VERSION ""

NS_ :

BS_:

BU_:

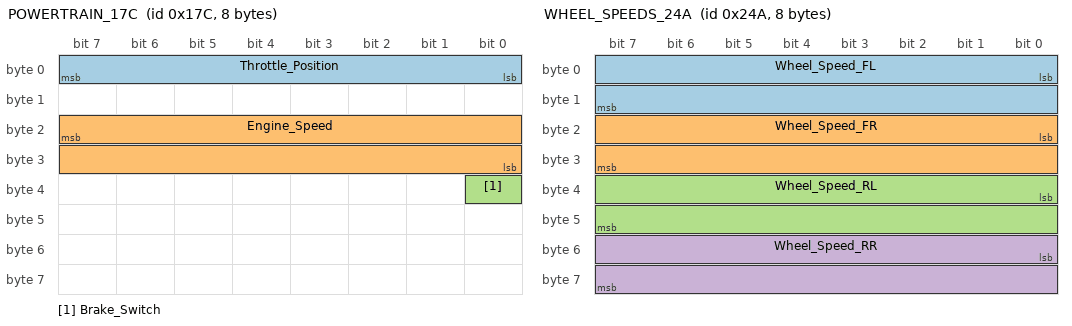
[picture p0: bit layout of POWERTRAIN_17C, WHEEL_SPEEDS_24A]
BO_ 380 POWERTRAIN_17C: 8 Vector__XXX
 SG_ Throttle_Position : 7|8@0+ (1,0) [0|255] "" Vector__XXX
 SG_ Engine_Speed : 23|16@0+ (1,0) [0|15000] "rpm" Vector__XXX
 SG_ Brake_Switch : 32|1@0+ (1,0) [0|1] "" Vector__XXX

BO_ 586 WHEEL_SPEEDS_24A: 8 Vector__XXX
 SG_ Wheel_Speed_FL : 0|16@1+ (0.15625,0) [0|100] "m/s" Vector__XXX
 SG_ Wheel_Speed_FR : 16|16@1+ (0.15625,0) [0|100] "m/s" Vector__XXX
 SG_ Wheel_Speed_RL : 32|16@1+ (0.15625,0) [0|100] "m/s" Vector__XXX
 SG_ Wheel_Speed_RR : 48|16@1+ (0.16525,0) [0|100] "m/s" Vector__XXX
